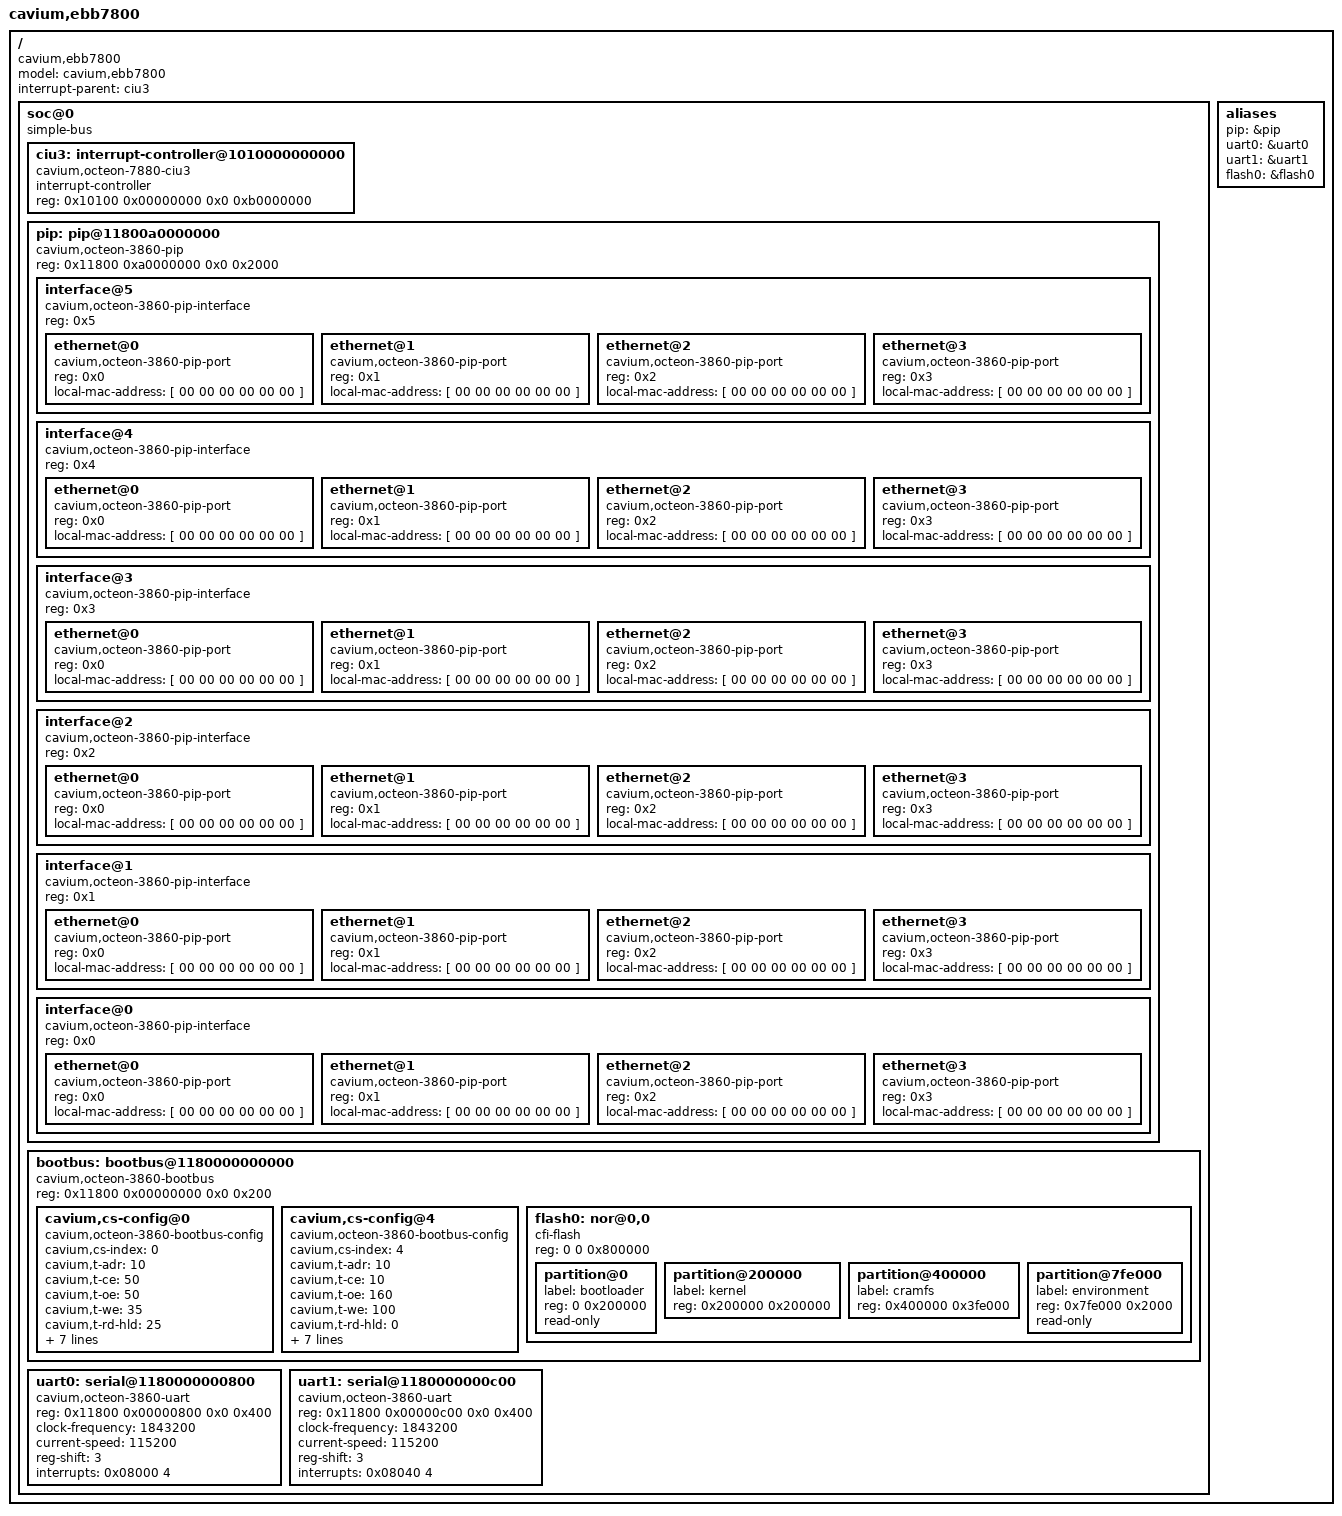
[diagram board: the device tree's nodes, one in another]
/dts-v1/;
/*
 * Cavium Inc. sim CN7800
 */
/ {
	model = "cavium,ebb7800";
	compatible = "cavium,ebb7800";
	#address-cells = <2>;
	#size-cells = <2>;
	interrupt-parent = <&ciu3>;

	soc@0 {
		compatible = "simple-bus";
		#address-cells = <2>;
		#size-cells = <2>;
		ranges; /* Direct mapping */

		ciu3: interrupt-controller@1010000000000 {
			compatible = "cavium,octeon-7880-ciu3";
			interrupt-controller;
			/* Interrupts are specified by two parts:
			 * 1) Source number (20 significant bits)
			 * 2) Trigger type: (4 == level, 1 == edge)
			 */
			#address-cells = <0>;
			#interrupt-cells = <2>;
			reg = <0x10100 0x00000000 0x0 0xb0000000>;
		};

		pip: pip@11800a0000000 {
			compatible = "cavium,octeon-3860-pip";
			#address-cells = <1>;
			#size-cells = <0>;
			reg = <0x11800 0xa0000000 0x0 0x2000>;

			interface@5 {
				compatible = "cavium,octeon-3860-pip-interface";
				#address-cells = <1>;
				#size-cells = <0>;
				reg = <0x5>; /* interface */

				ethernet@0 {
					compatible = "cavium,octeon-3860-pip-port";
					reg = <0x0>; /* Port */
					local-mac-address = [ 00 00 00 00 00 00 ];
				};
				ethernet@1 {
					compatible = "cavium,octeon-3860-pip-port";
					reg = <0x1>; /* Port */
					local-mac-address = [ 00 00 00 00 00 00 ];
				};
				ethernet@2 {
					compatible = "cavium,octeon-3860-pip-port";
					reg = <0x2>; /* Port */
					local-mac-address = [ 00 00 00 00 00 00 ];
				};
				ethernet@3 {
					compatible = "cavium,octeon-3860-pip-port";
					reg = <0x3>; /* Port */
					local-mac-address = [ 00 00 00 00 00 00 ];
				};
			};

			interface@4 {
				compatible = "cavium,octeon-3860-pip-interface";
				#address-cells = <1>;
				#size-cells = <0>;
				reg = <0x4>; /* interface */

				ethernet@0 {
					compatible = "cavium,octeon-3860-pip-port";
					reg = <0x0>; /* Port */
					local-mac-address = [ 00 00 00 00 00 00 ];
				};
				ethernet@1 {
					compatible = "cavium,octeon-3860-pip-port";
					reg = <0x1>; /* Port */
					local-mac-address = [ 00 00 00 00 00 00 ];
				};
				ethernet@2 {
					compatible = "cavium,octeon-3860-pip-port";
					reg = <0x2>; /* Port */
					local-mac-address = [ 00 00 00 00 00 00 ];
				};
				ethernet@3 {
					compatible = "cavium,octeon-3860-pip-port";
					reg = <0x3>; /* Port */
					local-mac-address = [ 00 00 00 00 00 00 ];
				};
			};

			interface@3 {
				compatible = "cavium,octeon-3860-pip-interface";
				#address-cells = <1>;
				#size-cells = <0>;
				reg = <0x3>; /* interface */

				ethernet@0 {
					compatible = "cavium,octeon-3860-pip-port";
					reg = <0x0>; /* Port */
					local-mac-address = [ 00 00 00 00 00 00 ];
				};
				ethernet@1 {
					compatible = "cavium,octeon-3860-pip-port";
					reg = <0x1>; /* Port */
					local-mac-address = [ 00 00 00 00 00 00 ];
				};
				ethernet@2 {
					compatible = "cavium,octeon-3860-pip-port";
					reg = <0x2>; /* Port */
					local-mac-address = [ 00 00 00 00 00 00 ];
				};
				ethernet@3 {
					compatible = "cavium,octeon-3860-pip-port";
					reg = <0x3>; /* Port */
					local-mac-address = [ 00 00 00 00 00 00 ];
				};
			};

			interface@2 {
				compatible = "cavium,octeon-3860-pip-interface";
				#address-cells = <1>;
				#size-cells = <0>;
				reg = <0x2>; /* interface */

				ethernet@0 {
					compatible = "cavium,octeon-3860-pip-port";
					reg = <0x0>; /* Port */
					local-mac-address = [ 00 00 00 00 00 00 ];
				};
				ethernet@1 {
					compatible = "cavium,octeon-3860-pip-port";
					reg = <0x1>; /* Port */
					local-mac-address = [ 00 00 00 00 00 00 ];
				};
				ethernet@2 {
					compatible = "cavium,octeon-3860-pip-port";
					reg = <0x2>; /* Port */
					local-mac-address = [ 00 00 00 00 00 00 ];
				};
				ethernet@3 {
					compatible = "cavium,octeon-3860-pip-port";
					reg = <0x3>; /* Port */
					local-mac-address = [ 00 00 00 00 00 00 ];
				};
			};

			interface@1 {
				compatible = "cavium,octeon-3860-pip-interface";
				#address-cells = <1>;
				#size-cells = <0>;
				reg = <0x1>; /* interface */

				ethernet@0 {
					compatible = "cavium,octeon-3860-pip-port";
					reg = <0x0>; /* Port */
					local-mac-address = [ 00 00 00 00 00 00 ];
				};
				ethernet@1 {
					compatible = "cavium,octeon-3860-pip-port";
					reg = <0x1>; /* Port */
					local-mac-address = [ 00 00 00 00 00 00 ];
				};
				ethernet@2 {
					compatible = "cavium,octeon-3860-pip-port";
					reg = <0x2>; /* Port */
					local-mac-address = [ 00 00 00 00 00 00 ];
				};
				ethernet@3 {
					compatible = "cavium,octeon-3860-pip-port";
					reg = <0x3>; /* Port */
					local-mac-address = [ 00 00 00 00 00 00 ];
				};
			};

			interface@0 {
				compatible = "cavium,octeon-3860-pip-interface";
				#address-cells = <1>;
				#size-cells = <0>;
				reg = <0x0>; /* interface */

				ethernet@0 {
					compatible = "cavium,octeon-3860-pip-port";
					reg = <0x0>; /* Port */
					local-mac-address = [ 00 00 00 00 00 00 ];
				};
				ethernet@1 {
					compatible = "cavium,octeon-3860-pip-port";
					reg = <0x1>; /* Port */
					local-mac-address = [ 00 00 00 00 00 00 ];
				};
				ethernet@2 {
					compatible = "cavium,octeon-3860-pip-port";
					reg = <0x2>; /* Port */
					local-mac-address = [ 00 00 00 00 00 00 ];
				};
				ethernet@3 {
					compatible = "cavium,octeon-3860-pip-port";
					reg = <0x3>; /* Port */
					local-mac-address = [ 00 00 00 00 00 00 ];
				};
			};
		};

		bootbus: bootbus@1180000000000 {
			compatible = "cavium,octeon-3860-bootbus";
			reg = <0x11800 0x00000000 0x0 0x200>;
			/* The chip select number and offset */
			#address-cells = <2>;
			/* The size of the chip select region */
			#size-cells = <1>;
			ranges = <0 0  0       0x1f400000  0xc00000>,
				 <1 0  0x10000 0x10000000  0>,
				 <2 0  0x10000 0x20000000  0>,
				 <3 0  0x10000 0x30000000  0>,
				 <4 0  0x10000 0x1d020000  0x10000>,
				 <5 0  0x10000 0x50000000  0x10000>,
				 <6 0  0x10000 0x60000000  0x10000>,
				 <7 0  0x10000 0x90000000  0>;

			cavium,cs-config@0 {
				compatible = "cavium,octeon-3860-bootbus-config";
				cavium,cs-index = <0>;
				cavium,t-adr  = <10>;
				cavium,t-ce   = <50>;
				cavium,t-oe   = <50>;
				cavium,t-we   = <35>;
				cavium,t-rd-hld = <25>;
				cavium,t-wr-hld = <35>;
				cavium,t-pause  = <0>;
				cavium,t-wait   = <300>;
				cavium,t-page   = <25>;
				cavium,t-rd-dly = <0>;

				cavium,pages     = <0>;
				cavium,bus-width = <8>;
			};
			cavium,cs-config@4 {
				compatible = "cavium,octeon-3860-bootbus-config";
				cavium,cs-index = <4>;
				cavium,t-adr  = <10>;
				cavium,t-ce   = <10>;
				cavium,t-oe   = <160>;
				cavium,t-we   = <100>;
				cavium,t-rd-hld = <0>;
				cavium,t-wr-hld = <0>;
				cavium,t-pause  = <50>;
				cavium,t-wait   = <300>;
				cavium,t-page   = <300>;
				cavium,t-rd-dly = <10>;

				cavium,pages     = <0>;
				cavium,bus-width = <8>;
			};
			flash0: nor@0,0 {
				compatible = "cfi-flash";
				reg = <0 0 0x800000>;
				#address-cells = <1>;
				#size-cells = <1>;

				partition@0 {
					label = "bootloader";
					reg = <0 0x200000>;
					read-only;
				};
				partition@200000 {
					label = "kernel";
					reg = <0x200000 0x200000>;
				};
				partition@400000 {
					label = "cramfs";
					reg = <0x400000 0x3fe000>;
				};
				partition@7fe000 {
					label = "environment";
					reg = <0x7fe000 0x2000>;
					read-only;
				};
			};
		};
		uart0: serial@1180000000800 {
			compatible = "cavium,octeon-3860-uart","ns16550";
			reg = <0x11800 0x00000800 0x0 0x400>;
			clock-frequency = <1843200>;
			current-speed = <115200>;
			reg-shift = <3>;
			interrupts = <0x08000 4>;
		};

		uart1: serial@1180000000c00 {
			compatible = "cavium,octeon-3860-uart","ns16550";
			reg = <0x11800 0x00000c00 0x0 0x400>;
			clock-frequency = <1843200>;
			current-speed = <115200>;
			reg-shift = <3>;
			interrupts = <0x08040 4>;
		};
	};
	aliases {
		pip = &pip;
		uart0 = &uart0;
		uart1 = &uart1;
		flash0 = &flash0;
	};
 };
